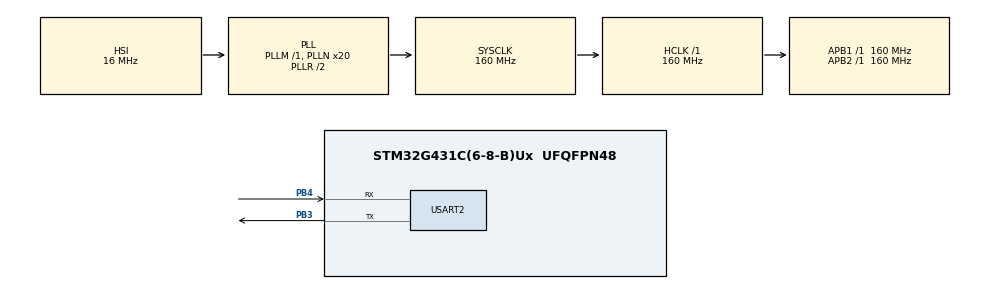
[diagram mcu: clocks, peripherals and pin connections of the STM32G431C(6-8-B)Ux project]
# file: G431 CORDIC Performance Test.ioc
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Mcu.Family=STM32G4
Mcu.Name=STM32G431C(6-8-B)Ux
Mcu.Package=UFQFPN48
NVIC.PriorityGroup=NVIC_PRIORITYGROUP_4
PA13.Mode=Serial_Wire
PA13.Signal=SYS_JTMS-SWDIO
PA14.Mode=Serial_Wire
PA14.Signal=SYS_JTCK-SWCLK
PB3.Mode=Asynchronous
PB3.Signal=USART2_TX
PB4.Mode=Asynchronous
PB4.Signal=USART2_RX
ProjectManager.HeapSize=0x200
ProjectManager.StackSize=0x400
ProjectManager.TargetToolchain=STM32CubeIDE
RCC.ADC12Freq_Value=160000000
RCC.AHBFreq_Value=160000000
RCC.APB1Freq_Value=160000000
RCC.APB1TimFreq_Value=160000000
RCC.APB2Freq_Value=160000000
RCC.APB2TimFreq_Value=160000000
RCC.CortexFreq_Value=160000000
RCC.EXTERNAL_CLOCK_VALUE=12288000
RCC.HCLKFreq_Value=160000000
RCC.HSE_VALUE=8000000
RCC.HSI48_VALUE=48000000
RCC.HSI_VALUE=16000000
RCC.LSE_VALUE=32768
RCC.PLLN=20
RCC.SYSCLKFreq_VALUE=160000000
RCC.SYSCLKSource=RCC_SYSCLKSOURCE_PLLCLK
RCC.USBFreq_Value=160000000
RCC.VCOOutputFreq_Value=320000000
USART2.VirtualMode-Asynchronous=VM_ASYNC
VP_CORDIC_VS_CORDIC.Mode=CORDIC_Activate
VP_SYS_VS_DBSignals.Mode=DisableDeadBatterySignals
board=custom

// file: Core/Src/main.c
/* USER CODE BEGIN Header */
/**
  ******************************************************************************
  * @file           : main.c
  * @brief          : Main program body
  ******************************************************************************
  * @attention
  *
  * Copyright (c) 2022 STMicroelectronics.
  * All rights reserved.
  *
  * This software is licensed under terms that can be found in the LICENSE file
  * in the root directory of this software component.
  * If no LICENSE file comes with this software, it is provided AS-IS.
  *
  ******************************************************************************
  */
/* USER CODE END Header */
#include "main.h"

/* USER CODE BEGIN Includes */
#include <math.h>
#include <string.h>
#include <stdio.h>
/* USER CODE END Includes */

/* USER CODE BEGIN PD */

#define Q31_TO_FLOAT(x) ((float)(x) / (float)(0x80000000))
#define FLOAT_TO_Q31(x) ((int32_t)((float)(x) * (float)0x7FFFFFFF))

/**
 * Wrap angle in radians to [−pi pi]
 */
static inline float wrapToPi(float value) {
  return fmodf(value + M_PI, 2*M_PI) - M_PI;
}

/* USER CODE END PD */

 CORDIC_HandleTypeDef hcordic;

UART_HandleTypeDef huart2;

void SystemClock_Config(void);
static void MX_GPIO_Init(void);
static void MX_CORDIC_Init(void);
static void MX_USART2_UART_Init(void);

int main(void)
{

  /* MCU Configuration--------------------------------------------------------*/

  /* Reset of all peripherals, Initializes the Flash interface and the Systick. */
  HAL_Init();

  /* Configure the system clock */
  SystemClock_Config();

  /* Initialize all configured peripherals */
  MX_GPIO_Init();
  MX_CORDIC_Init();
  MX_USART2_UART_Init();
  /* USER CODE BEGIN 2 */

  CORDIC_ConfigTypeDef config = {
    CORDIC_FUNCTION_COSINE, // ouput : cosine, then sine
    CORDIC_SCALE_0, // not used
    CORDIC_INSIZE_32BITS, // q31
    CORDIC_OUTSIZE_32BITS, // q31
    CORDIC_NBWRITE_1, // ARG2 is 1 default
    CORDIC_NBREAD_2, // read cosine and sine
    CORDIC_PRECISION_6CYCLES // better than 10-3
  };
  HAL_CORDIC_Configure(&hcordic, &config);

  /* USER CODE END 2 */

  /* Infinite loop */
  while (1)
  {

    /* USER CODE BEGIN 3 */
    float normal_sum = 0;
    float cordic_sum = 0;

    float theta;

    uint32_t start_t;
    uint32_t normal_t;
    uint32_t cordic_t;

    const uint32_t N_ITERS = 10000;

    start_t = HAL_GetTick();
    for (uint32_t i=0; i<N_ITERS; i+=1) {
      theta = (float)i;

      normal_sum += cosf(theta) * 0.5 + sinf(theta) * 0.25;
    }
    normal_t = HAL_GetTick() - start_t;

    int32_t cordic_arg[1];
    int32_t cordic_res[2];

    start_t = HAL_GetTick();
    for (uint32_t i=0; i<N_ITERS; i+=1) {
      theta = (float)i;

      cordic_arg[0] = FLOAT_TO_Q31(wrapToPi(theta)/M_PI);

      float cosine_theta;
      float sine_theta;
      HAL_StatusTypeDef result = HAL_CORDIC_Calculate(&hcordic, cordic_arg, cordic_res, 1, 10);

      if(HAL_OK==result) {
        cosine_theta = Q31_TO_FLOAT(cordic_res[0]);
        sine_theta = Q31_TO_FLOAT(cordic_res[1]);
      }

      cordic_sum += cosine_theta * 0.5 + sine_theta * 0.25;
    }
    cordic_t = HAL_GetTick() - start_t;

    char str[128];
    sprintf(str, "normal: %f %d, cordic: %f %d\r\n", normal_sum, normal_t, cordic_sum, cordic_t);
    HAL_UART_Transmit(&huart2, (uint8_t *)str, strlen(str), 100);

    HAL_Delay(100);
  }
  /* USER CODE END 3 */
}

void SystemClock_Config(void)
{
  RCC_OscInitTypeDef RCC_OscInitStruct = {0};
  RCC_ClkInitTypeDef RCC_ClkInitStruct = {0};

  /** Configure the main internal regulator output voltage
  */
  HAL_PWREx_ControlVoltageScaling(PWR_REGULATOR_VOLTAGE_SCALE1_BOOST);

  /** Initializes the RCC Oscillators according to the specified parameters
  * in the RCC_OscInitTypeDef structure.
  */
  RCC_OscInitStruct.OscillatorType = RCC_OSCILLATORTYPE_HSI;
  RCC_OscInitStruct.HSIState = RCC_HSI_ON;
  RCC_OscInitStruct.HSICalibrationValue = RCC_HSICALIBRATION_DEFAULT;
  RCC_OscInitStruct.PLL.PLLState = RCC_PLL_ON;
  RCC_OscInitStruct.PLL.PLLSource = RCC_PLLSOURCE_HSI;
  RCC_OscInitStruct.PLL.PLLM = RCC_PLLM_DIV1;
  RCC_OscInitStruct.PLL.PLLN = 20;
  RCC_OscInitStruct.PLL.PLLP = RCC_PLLP_DIV2;
  RCC_OscInitStruct.PLL.PLLQ = RCC_PLLQ_DIV2;
  RCC_OscInitStruct.PLL.PLLR = RCC_PLLR_DIV2;
  if (HAL_RCC_OscConfig(&RCC_OscInitStruct) != HAL_OK)
  {
    Error_Handler();
  }

  /** Initializes the CPU, AHB and APB buses clocks
  */
  RCC_ClkInitStruct.ClockType = RCC_CLOCKTYPE_HCLK|RCC_CLOCKTYPE_SYSCLK
                              |RCC_CLOCKTYPE_PCLK1|RCC_CLOCKTYPE_PCLK2;
  RCC_ClkInitStruct.SYSCLKSource = RCC_SYSCLKSOURCE_PLLCLK;
  RCC_ClkInitStruct.AHBCLKDivider = RCC_SYSCLK_DIV1;
  RCC_ClkInitStruct.APB1CLKDivider = RCC_HCLK_DIV1;
  RCC_ClkInitStruct.APB2CLKDivider = RCC_HCLK_DIV1;

  if (HAL_RCC_ClockConfig(&RCC_ClkInitStruct, FLASH_LATENCY_4) != HAL_OK)
  {
    Error_Handler();
  }
}

static void MX_CORDIC_Init(void)
{

  hcordic.Instance = CORDIC;
  if (HAL_CORDIC_Init(&hcordic) != HAL_OK)
  {
    Error_Handler();
  }

}

static void MX_USART2_UART_Init(void)
{

  huart2.Instance = USART2;
  huart2.Init.BaudRate = 115200;
  huart2.Init.WordLength = UART_WORDLENGTH_8B;
  huart2.Init.StopBits = UART_STOPBITS_1;
  huart2.Init.Parity = UART_PARITY_NONE;
  huart2.Init.Mode = UART_MODE_TX_RX;
  huart2.Init.HwFlowCtl = UART_HWCONTROL_NONE;
  huart2.Init.OverSampling = UART_OVERSAMPLING_16;
  huart2.Init.OneBitSampling = UART_ONE_BIT_SAMPLE_DISABLE;
  huart2.Init.ClockPrescaler = UART_PRESCALER_DIV1;
  huart2.AdvancedInit.AdvFeatureInit = UART_ADVFEATURE_NO_INIT;
  if (HAL_UART_Init(&huart2) != HAL_OK)
  {
    Error_Handler();
  }
  if (HAL_UARTEx_SetTxFifoThreshold(&huart2, UART_TXFIFO_THRESHOLD_1_8) != HAL_OK)
  {
    Error_Handler();
  }
  if (HAL_UARTEx_SetRxFifoThreshold(&huart2, UART_RXFIFO_THRESHOLD_1_8) != HAL_OK)
  {
    Error_Handler();
  }
  if (HAL_UARTEx_DisableFifoMode(&huart2) != HAL_OK)
  {
    Error_Handler();
  }

}

static void MX_GPIO_Init(void)
{

  /* GPIO Ports Clock Enable */
  __HAL_RCC_GPIOA_CLK_ENABLE();
  __HAL_RCC_GPIOB_CLK_ENABLE();

}

void Error_Handler(void)
{
  __disable_irq();
  while (1)
  {
  }
}
